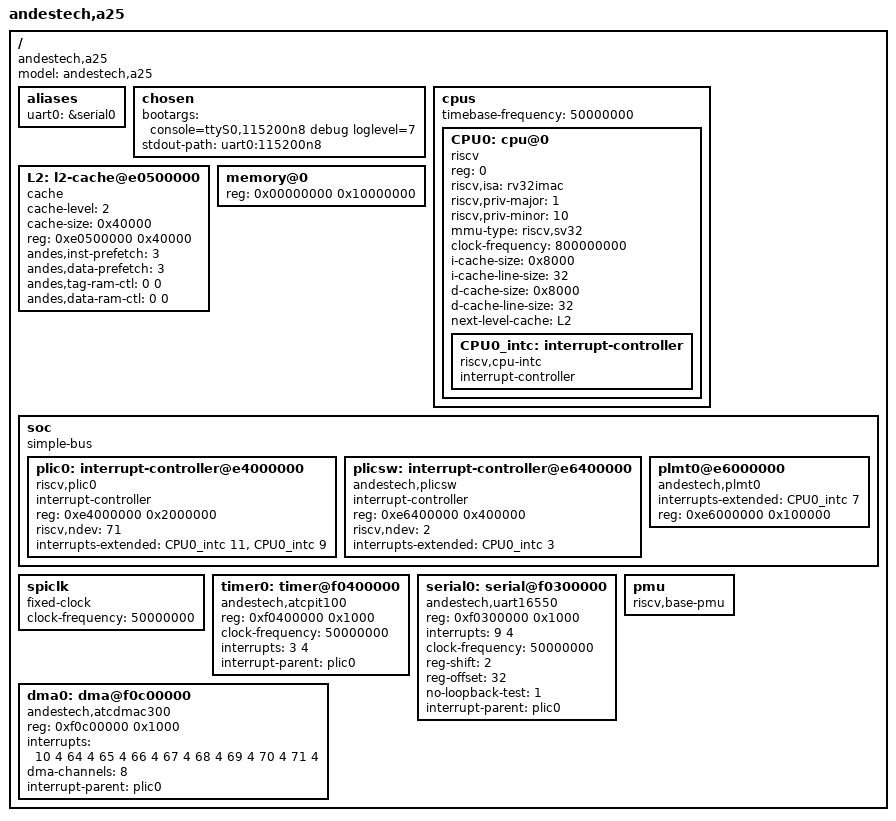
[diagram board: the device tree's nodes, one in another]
// SPDX-License-Identifier: (GPL-2.0 OR MIT)
//
// Device tree adapted for the Gowin AE350 SoC on the Sipeed Tang Mega 138K Pro
// Dock (mega_138K_test gateware). Differences from the mainline Andes AE350
// reference board:
//   - single core (the Gowin demo SoC is 1 hart), no FPU (rv32imac)
//   - real on-board clocks:
//       * machine timer (PLMT mtime) = 50 MHz  (demo_plmt uses 2*OSCFREQ ticks
//         for 2 s, OSCFREQ = 50 MHz)
//       * APB peripheral clock (UART2, PIT)    = 50 MHz  (measured on hardware)
//   - DRAM = 256 MB DDR3 at 0x0 (DDR3_ADDR[13:0] row + 8 banks + x16)
//   - core clock 800 MHz (informational)

/dts-v1/;

#include "binman.dtsi"
#include "ae350-u-boot.dtsi"

/ {
	#address-cells = <1>;
	#size-cells = <1>;
	compatible = "andestech,a25";
	model = "andestech,a25";

	aliases {
		uart0 = &serial0;
	};

	chosen {
		bootargs = "console=ttyS0,115200n8 debug loglevel=7";
		stdout-path = "uart0:115200n8";
	};

	cpus {
		#address-cells = <1>;
		#size-cells = <0>;
		timebase-frequency = <50000000>;	/* PLMT mtime = 50 MHz */
		CPU0: cpu@0 {
			device_type = "cpu";
			reg = <0>;
			status = "okay";
			compatible = "riscv";
			riscv,isa = "rv32imac";		/* no FPU on this SoC */
			riscv,priv-major = <1>;
			riscv,priv-minor = <10>;
			mmu-type = "riscv,sv32";
			clock-frequency = <800000000>;	/* core clock */
			i-cache-size = <0x8000>;
			i-cache-line-size = <32>;
			d-cache-size = <0x8000>;
			d-cache-line-size = <32>;
			next-level-cache = <&L2>;
			CPU0_intc: interrupt-controller {
				#interrupt-cells = <1>;
				interrupt-controller;
				compatible = "riscv,cpu-intc";
			};
		};
	};

	L2: l2-cache@e0500000 {
		compatible = "cache";
		cache-level = <2>;
		cache-size = <0x40000>;
		reg = <0xe0500000 0x40000>;
		andes,inst-prefetch = <3>;
		andes,data-prefetch = <3>;
		/* The value format is <XRAMOCTL XRAMICTL> */
		andes,tag-ram-ctl = <0 0>;
		andes,data-ram-ctl = <0 0>;
	};

	memory@0 {
		device_type = "memory";
		reg = <0x00000000 0x10000000>;	/* 256 MB DDR3 */
	};

	soc {
		#address-cells = <1>;
		#size-cells = <1>;
		compatible = "simple-bus";
		ranges;

		plic0: interrupt-controller@e4000000 {
			compatible = "riscv,plic0";
			#interrupt-cells = <2>;
			interrupt-controller;
			reg = <0xe4000000 0x2000000>;
			riscv,ndev=<71>;
			interrupts-extended = <&CPU0_intc 11 &CPU0_intc 9>;
		};

		plicsw: interrupt-controller@e6400000 {
			compatible = "andestech,plicsw";
			#interrupt-cells = <1>;
			interrupt-controller;
			reg = <0xe6400000 0x400000>;
			riscv,ndev=<2>;
			interrupts-extended = <&CPU0_intc 3>;
		};

		plmt0@e6000000 {
			compatible = "andestech,plmt0";
			interrupts-extended = <&CPU0_intc 7>;
			reg = <0xe6000000 0x100000>;
		};
	};

	spiclk: spiclk {
		#clock-cells = <0>;
		compatible = "fixed-clock";
		clock-frequency = <50000000>;	/* ATCSPI200 input = APB 50 MHz */
	};

	timer0: timer@f0400000 {
		compatible = "andestech,atcpit100";
		reg = <0xf0400000 0x1000>;
		clock-frequency = <50000000>;	/* APB = 50 MHz */
		interrupts = <3 4>;
		interrupt-parent = <&plic0>;
	};

	serial0: serial@f0300000 {
		compatible = "andestech,uart16550", "ns16550a";
		reg = <0xf0300000 0x1000>;
		interrupts = <9 4>;
		clock-frequency = <50000000>;	/* APB = 50 MHz (was 19660800) */
		reg-shift = <2>;
		reg-offset = <32>;
		no-loopback-test = <1>;
		interrupt-parent = <&plic0>;
	};

	dma0: dma@f0c00000 {
		compatible = "andestech,atcdmac300";
		reg = <0xf0c00000 0x1000>;
		interrupts = <10 4 64 4 65 4 66 4 67 4 68 4 69 4 70 4 71 4>;
		dma-channels = <8>;
		interrupt-parent = <&plic0>;
	};

	pmu {
		compatible = "riscv,base-pmu";
	};

	/* SD card is driven by the apb_sd_top HW controller on the external APB
	 * (0xF8000000) via the custom `sdread` command, not the atcspi200 SPI
	 * master (whose U-Boot driver is SPI-NOR-flash only). No DT node needed. */
};
